# daric register map
Vendor: cramium
Registers are 32-bit, read-write, reset 0x0 unless marked. A register's access mark holds for its fields unless they carry their own. Offsets are from the block's base; [hi:lo] are bit positions; {n}, {i} and the like mark numbered series; 'fields as' and 'values as' point back to an identical list.

## QFC
Base 0x40010000
0x00 SFR_IO — See file:///F:/code/cram-nto/modules/core/rtl/qfc.sv
  [7:0] sfr_io — sfr_io read/write control register
0x04 SFR_AR — See file:///F:/code/cram-nto/modules/core/rtl/qfc.sv
  [31:0] sfr_ar — sfr_ar performs action on write of value: 0x5a
0x08 SFR_IODRV — See file:///F:/code/cram-nto/modules/core/rtl/qfc.sv
  [11:0] paddrvsel — paddrvsel read/write control register
0x10 CR_XIP_ADDRMODE — See file:///F:/code/cram-nto/modules/core/rtl/qfc.sv
  [1:0] cr_xip_addrmode — cr_xip_addrmode read/write control register
0x14 CR_XIP_OPCODE — See file:///F:/code/cram-nto/modules/core/rtl/qfc.sv
  [31:0] cr_xip_opcode — cr_xip_opcode read/write control register
0x18 CR_XIP_WIDTH — See file:///F:/code/cram-nto/modules/core/rtl/qfc.sv
  [5:0] cr_xip_width — cr_xip_width read/write control register
0x1C CR_XIP_SSEL — See file:///F:/code/cram-nto/modules/core/rtl/qfc.sv
  [6:0] cr_xip_ssel — cr_xip_ssel read/write control register
0x20 CR_XIP_DUMCYC — See file:///F:/code/cram-nto/modules/core/rtl/qfc.sv
  [15:0] cr_xip_dumcyc — cr_xip_dumcyc read/write control register
0x24 CR_XIP_CFG — See file:///F:/code/cram-nto/modules/core/rtl/qfc.sv
  [14:0] cr_xip_cfg — cr_xip_cfg read/write control register
{0x40+4i} CR_AESKEY_AESKEYIN{i} (i=0..3) — See file:///F:/code/cram-nto/modules/core/rtl/qfc.sv
  [31:0] aeskeyin{i} — cr_aeskey read/write control register
0x50 CR_AESENA — See file:///F:/code/cram-nto/modules/core/rtl/qfc.sv
  [0] cr_aesena — cr_aesena read/write control register

## MBOX_APB
Base 0x40013000
0x00 SFR_WDATA — See file:///F:/code/cram-nto/modules/vexriscv/lib/mbox_v0.1.sv
  [31:0] sfr_wdata — sfr_wdata read/write control register
0x04 SFR_RDATA — See file:///F:/code/cram-nto/modules/vexriscv/lib/mbox_v0.1.sv
  [31:0] sfr_rdata — sfr_rdata read only status register
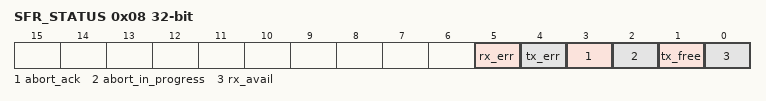
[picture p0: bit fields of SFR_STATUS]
0x08 SFR_STATUS — See file:///F:/code/cram-nto/modules/vexriscv/lib/mbox_v0.1.sv
  [5] rx_err — rx_err read only status register
  [4] tx_err — tx_err read only status register
  [3] abort_ack — abort_ack read only status register
  [2] abort_in_progress — abort_in_progress read only status register
  [1] tx_free — tx_free read only status register
  [0] rx_avail — rx_avail read only status register
0x18 SFR_ABORT — See file:///F:/code/cram-nto/modules/vexriscv/lib/mbox_v0.1.sv
  [31:0] sfr_abort — sfr_abort performs action on write of value: 0x1
0x1C SFR_DONE — See file:///F:/code/cram-nto/modules/vexriscv/lib/mbox_v0.1.sv
  [31:0] sfr_done — sfr_done performs action on write of value: 0x1

## RRC
Base 0x40000000
0x00 SFR_RRCCR — See file:///F:/code/cram-nto/modules/rrc/rtl/rrc.sv
  [31:0] sfr_rrccr — sfr_rrccr read/write control register
0x04 SFR_RRCFD — See file:///F:/code/cram-nto/modules/rrc/rtl/rrc.sv
  [4:0] sfr_rrcfd — sfr_rrcfd read/write control register
0x08 SFR_RRCSR — See file:///F:/code/cram-nto/modules/rrc/rtl/rrc.sv
  [9:0] sfr_rrcsr — sfr_rrcsr read only status register
0x0C SFR_RRCFR — See file:///F:/code/cram-nto/modules/rrc/rtl/rrc.sv
  [4:0] sfr_rrcfr — sfr_rrcfr flag register. `1` means event happened, write back `1` in respective bit position to clear the flag
0x14 SFR_RRCSR_SET0 — See file:///F:/code/cram-nto/modules/rrc/rtl/rrc.sv
  [31:0] trc_set_failure — trc_set_failure read only status register
0x18 SFR_RRCSR_SET1 — See file:///F:/code/cram-nto/modules/rrc/rtl/rrc.sv
  [31:0] trc_set_failure — trc_set_failure read only status register
0x1C SFR_RRCSR_RST0 — See file:///F:/code/cram-nto/modules/rrc/rtl/rrc.sv
  [31:0] trc_reset_failure — trc_reset_failure read only status register
0x20 SFR_RRCSR_RST1 — See file:///F:/code/cram-nto/modules/rrc/rtl/rrc.sv
  fields as SFR_RRCSR_RST0
0x24 SFR_RRCSR_RD0 — See file:///F:/code/cram-nto/modules/rrc/rtl/rrc.sv
  [31:0] trc_fourth_read_failure — trc_fourth_read_failure read only status register
0x28 SFR_RRCSR_RD1 — See file:///F:/code/cram-nto/modules/rrc/rtl/rrc.sv
  fields as SFR_RRCSR_RD0
0xF0 SFR_RRCAR — See file:///F:/code/cram-nto/modules/rrc/rtl/rrc.sv
  [31:0] sfr_rrcar — sfr_rrcar performs action on write of value: 0x2468
